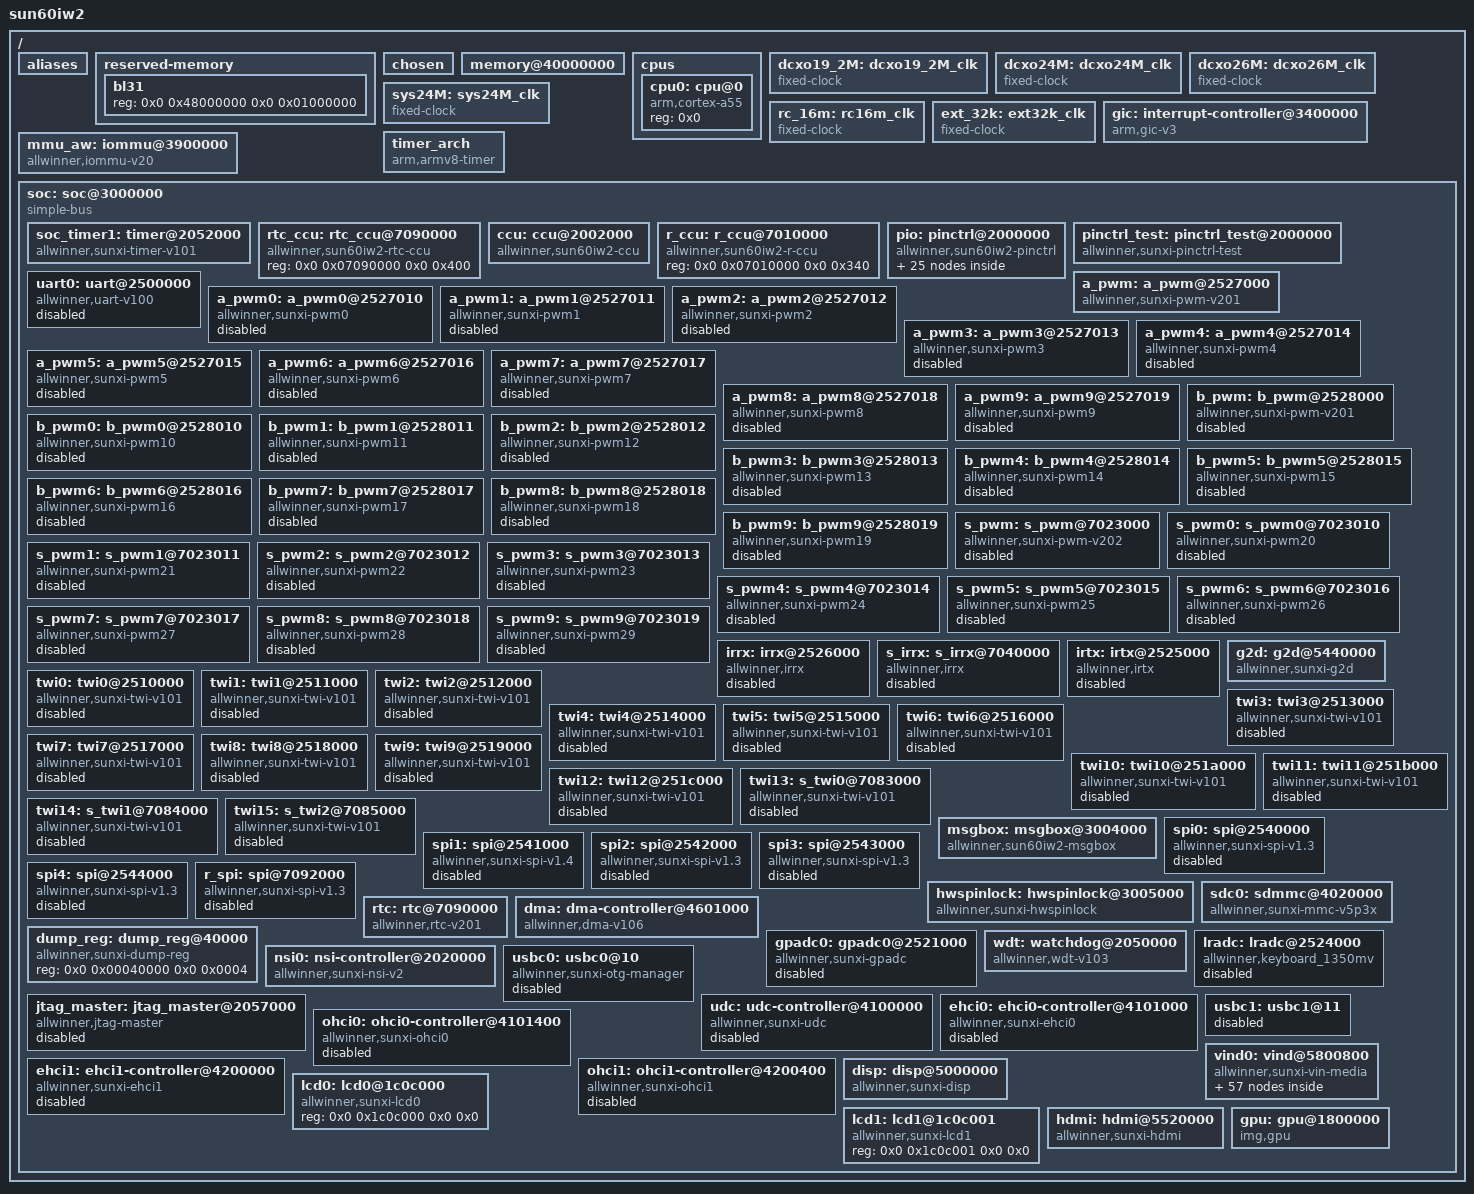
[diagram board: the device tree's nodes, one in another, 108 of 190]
// SPDX-License-Identifier: (GPL-2.0+ or MIT)
#include <dt-bindings/clock/sun60iw2-ccu.h>
#include <dt-bindings/clock/sun60iw2-rtc.h>
#include <dt-bindings/clock/sun60iw2-r-ccu.h>
#include <dt-bindings/gpio/gpio.h>
#include <dt-bindings/gpio/sun4i-gpio.h>
#include <dt-bindings/interrupt-controller/arm-gic.h>
#include <dt-bindings/reset/sun60iw2-ccu.h>
#include <dt-bindings/reset/sun60iw2-r-ccu.h>
#include <dt-bindings/power/a523-power.h>
#include <dt-bindings/phy/phy.h>
#include <dt-bindings/thermal/thermal.h>
#include <dt-bindings/spi/sunxi-spi.h>

/ {
	model = "sun60iw2";
	interrupt-parent = <&gic>;
	#address-cells = <2>;
	#size-cells = <2>;

	aliases {
		serial0 = &uart0;
		ir0 = &irrx;
		ir1 = &s_irrx;
		ir2 = &irtx;
		twi0 = &twi0;
		twi1 = &twi1;
		twi2 = &twi2;
		twi3 = &twi3;
		twi4 = &twi4;
		twi5 = &twi5;
		twi6 = &twi6;
		twi7 = &twi7;
		twi8 = &twi8;
		twi9 = &twi9;
		twi10 = &twi10;
		twi11 = &twi11;
		twi12 = &twi12;
		twi13 = &twi13;
		twi14 = &twi14;
		twi15 = &twi15;
		spi0 = &spi0;
		spi1 = &spi1;
		spi2 = &spi2;
		spi3 = &spi3;
		spi4 = &spi4;
		spi5 = &r_spi;
	};

	reserved-memory {
		#address-cells = <2>;
		#size-cells = <2>;
		ranges;

		bl31 {
			reg = <0x0 0x48000000 0x0 0x01000000>;
		};
	};

	chosen {
		bootargs = "earlyprintk=sunxi-uart,0x2500000 loglevel=8 initcall_debug=0 console=ttyS0 init=/init";
		linux,initrd-start = <0x0 0x0>;
		linux,initrd-end = <0x0 0x0>;
	};

	/* avoid panic when memory-node err(from uboot) */
	memory@40000000 {
		device_type = "memory";
		reg = <0x00000000 0x40000000 0x00000000 0x20000000>;
	};

	cpus {
		#address-cells = <1>;
		#size-cells = <0>;

		cpu0: cpu@0 {
			device_type = "cpu";
			compatible = "arm,cortex-a55";
			reg = <0x0>;
		};
	};

	dcxo19_2M: dcxo19_2M_clk {
		#clock-cells = <0>;
		compatible = "fixed-clock";
		clock-frequency = <19200000>;
		clock-output-names = "dcxo19_2M";
	};

	dcxo24M: dcxo24M_clk {
		#clock-cells = <0>;
		compatible = "fixed-clock";
		clock-frequency = <24000000>;
		clock-output-names = "dcxo24M";
	};

	dcxo26M: dcxo26M_clk {
		#clock-cells = <0>;
		compatible = "fixed-clock";
		clock-frequency = <26000000>;
		clock-output-names = "dcxo26M";
	};

	sys24M: sys24M_clk {
		#clock-cells = <0>;
		compatible = "fixed-clock";
		clock-frequency = <24000000>;
		clock-output-names = "sys24M";
	};

	rc_16m: rc16m_clk {
		#clock-cells = <0>;
		compatible = "fixed-clock";
		clock-frequency = <16000000>;
		clock-accuracy = <300000000>;
		clock-output-names = "rc-16m";
	};

	ext_32k: ext32k_clk {
		#clock-cells = <0>;
		compatible = "fixed-clock";
		clock-frequency = <32768>;
		clock-output-names = "ext-32k";
	};

	gic: interrupt-controller@3400000 {
		compatible = "arm,gic-v3";
		#interrupt-cells = <3>;
		#address-cells = <0>;
		interrupt-controller;
		reg = <0x0 0x03400000 0 0x10000>, /* GIC Dist */
		      <0x0 0x03460000 0 0xFF004>; /* GIC Re */
		interrupt-parent = <&gic>;
	};

	timer_arch {
		compatible = "arm,armv8-timer";
		interrupts = <GIC_PPI 13 (GIC_CPU_MASK_SIMPLE(4) | IRQ_TYPE_LEVEL_LOW)>,
			   <GIC_PPI 14 (GIC_CPU_MASK_SIMPLE(4) | IRQ_TYPE_LEVEL_LOW)>,
			   <GIC_PPI 11 (GIC_CPU_MASK_SIMPLE(4) | IRQ_TYPE_LEVEL_LOW)>,
			   <GIC_PPI 10 (GIC_CPU_MASK_SIMPLE(4) | IRQ_TYPE_LEVEL_LOW)>;
		clock-frequency = <24000000>;
		interrupt-parent = <&gic>;
		arm,no-tick-in-suspend;
	};

	mmu_aw: iommu@3900000 {
		compatible = "allwinner,iommu-v20";
		reg = <0x0 0x03900000 0x0 0x20000>;
		interrupts = <GIC_SPI 170 IRQ_TYPE_LEVEL_HIGH>,
		      <GIC_SPI 171 IRQ_TYPE_LEVEL_HIGH>;
		interrupt-names = "iommu-irq1","iommu-irq2";
		clocks = <&ccu CLK_IOMMU0_SYS_HCLK>,
		      <&ccu CLK_IOMMU0_SYS_PCLK>,
		      <&ccu CLK_IOMMU0_SYS_MCLK>,
		      <&ccu CLK_IOMMU1_SYS_HCLK>,
		      <&ccu CLK_IOMMU1_SYS_PCLK>,
		      <&ccu CLK_IOMMU1_SYS_MCLK>
		;
		clock-names = "iommu0-sys-hclk",
		      "iommu0-sys-pclk",
		      "iommu0-sys-mclk",
		      "iommu1-sys-hclk",
		      "iommu1-sys-pclk",
		      "iommu1-sys-mclk"
		;
		/* clock-frequency = <24000000>; */
		#iommu-cells = <2>;
		version=<0x16>;
		tlb_prefetch = <0x3007f>;
		tlb_invalid_mode = <0x1>;
		ptw_invalid_mode = <0x1>;
		masters = "USB", "CSI", "ISP", "VE_ENC", "dummy04", "dummy05",
			"VE_DEC0", "VE_DEC1", "DE0","DI","G2D","EINK", "DEBUG_MODE";
		valid_masters=<10>;
	};

	soc: soc@3000000 {
		compatible = "simple-bus";
		#address-cells = <2>;
		#size-cells = <2>;
		ranges;

		soc_timer1: timer@2052000 {
			compatible = "allwinner,sunxi-timer-v101";
			device_type = "soc_timer";
			reg = <0x0 0x02052000 0x0 0x400>;
			interrupt-parent = <&gic>;
			interrupts = <GIC_SPI 99 IRQ_TYPE_LEVEL_HIGH>;
			clocks = <&rtc_ccu CLK_OSC32K>;
		};

		rtc_ccu: rtc_ccu@7090000 {
			compatible = "allwinner,sun60iw2-rtc-ccu";
			reg = <0x0 0x07090000 0x0 0x400>;
			#clock-cells = <1>;
			#reset-cells = <1>;
		};

		ccu: ccu@2002000 {
			compatible = "allwinner,sun60iw2-ccu";
			reg = <0x0 0x02002000 0x0 0x2000>;
			clocks = <&dcxo24M>, <&rtc_ccu CLK_OSC32K>, <&rc_16m>;
			clock-names = "hosc", "losc", "iosc";
			#clock-cells = <1>;
			#reset-cells = <1>;
		};

		r_ccu: r_ccu@7010000 {
			compatible = "allwinner,sun60iw2-r-ccu";
			reg = <0x0 0x07010000 0x0 0x340>;
			#clock-cells = <1>;
			#reset-cells = <1>;
		};

		pio: pinctrl@2000000 {
			//#address-cells = <1>;
			//#size-cells = <0>;
			compatible = "allwinner,sun60iw2-pinctrl";
			reg = <0x0 0x02000000 0x0 0x800>;
			interrupts = <GIC_SPI 69 IRQ_TYPE_LEVEL_HIGH>,
				     <GIC_SPI 71 IRQ_TYPE_LEVEL_HIGH>,
				     <GIC_SPI 73 IRQ_TYPE_LEVEL_HIGH>,
				     <GIC_SPI 75 IRQ_TYPE_LEVEL_HIGH>,
				     <GIC_SPI 77 IRQ_TYPE_LEVEL_HIGH>,
				     <GIC_SPI 79 IRQ_TYPE_LEVEL_HIGH>,
				     <GIC_SPI 81 IRQ_TYPE_LEVEL_HIGH>;
			clocks = <&ccu CLK_APB1>, <&dcxo24M>, <&rtc_ccu CLK_OSC32K>;
			clock-names = "apb", "hosc", "losc";
			gpio-controller;
			#gpio-cells = <3>;
			interrupt-controller;
			#interrupt-cells = <3>;

			sdc0_pins_a: sdc0@0 {
				pins = "PF0", "PF1", "PF2",
						"PF3", "PF4", "PF5";
				function = "sd0";
				drive-strength = <40>;
				bias-pull-up;
				power-source = <3300>;
			};

			sdc0_pins_b: sdc0@1 {
				pins = "PF0", "PF1", "PF2",
						"PF3", "PF4", "PF5";
				function = "sd0";
				drive-strength = <40>;
				bias-pull-up;
				power-source = <1800>;
			};

			sdc0_pins_c: sdc0@2 {
				pins = "PF0", "PF1", "PF2",
						"PF3", "PF4", "PF5";
				function = "gpio_in";
			};

			/* TODO: add jtag pin */
			sdc0_pins_d: sdc0@3 {
				pins = "PF2", "PF4";
				function = "uart0";
				drive-strength = <10>;
				bias-pull-up;
			};

			sdc0_pins_e: sdc0@4 {
				pins = "PF0", "PF1", "PF3",
						"PF5";
				function = "jtag";
				drive-strength = <10>;
				bias-pull-up;
			};
			test_pins_a: test_pins@0 {
				pins = "PB0", "PB1";
				function = "test";
				drive-strength = <10>;
				bias-pull-up;
			};

			test_pins_b: test_pins@1 {
				pins = "PB0", "PB1";
				function = "gpio_in";
			};

			csi_mclk0_pins_a: csi_mclk0@0 {
				pins = "PE0";
				function = "mipi0";
				drive-strength = <20>;
			};

			csi_mclk0_pins_b: csi_mclk0@1 {
				pins = "PE0";
				function = "gpio_in";
			};

			csi_mclk1_pins_a: csi_mclk1@0 {
				pins = "PE5";
				function = "mipi1";
				drive-strength = <20>;
			};

			csi_mclk1_pins_b: csi_mclk1@1 {
				pins = "PE5";
				function = "gpio_in";
			};

			csi_mclk2_pins_a: csi_mclk2@0 {
				pins = "PE9";
				function = "mipi2";
				drive-strength = <20>;
			};

			csi_mclk2_pins_b: csi_mclk2@1 {
				pins = "PE9";
				function = "gpio_in";
			};

			ncsi0_bt656_pins_a: ncsi0_BT656@0 {
				pins = "PE0", "PE1", "PE2",
				"PE3", "PE4", "PE6", "PE7",
				"PE8", "PE9", "PE10";
				function = "ncsi";
				drive-strength = <20>;
			};

			ncsi0_bt656_pins_b: ncsi0_BT656@1 {
				pins = "PE0", "PE1", "PE2",
				"PE3", "PE4", "PE6", "PE7",
				"PE8", "PE9", "PE10";
				function = "gpio_in";
			};

			ncsi1_bt656_pins_a: ncsi1_BT656@0 {
				pins = "PK0", "PK1", "PK2",
				"PK19", "PK18", "PK17", "PK16",
				"PK15", "PK14", "PK13", "PK12";
				function = "ncsi";
				drive-strength = <20>;
			};

			ncsi1_bt656_pins_b: ncsi1_BT656@1 {
				pins = "PK0", "PK1", "PK2",
				"PK19", "PK18", "PK17", "PK16",
				"PK15", "PK14", "PK13", "PK12";
				function = "gpio_in";
			};

			ncsi1_bt1120_pins_a: ncsi1_BT1120@0 {
				pins = "PK0", "PK1", "PK2",
				"PK19", "PK18", "PK17", "PK16",
				"PK15", "PK14", "PK13", "PK12",
				"PK11", "PK10", "PK9", "PK8",
				"PK7", "PK6", "PK5", "PK4";
				function = "ncsi";
				drive-strength = <20>;
			};

			ncsi1_bt1120_pins_b: ncsi1_BT1120@1 {
				pins = "PK0", "PK1", "PK2",
				"PK19", "PK18", "PK17", "PK16",
				"PK15", "PK14", "PK13", "PK12",
				"PK11", "PK10", "PK9", "PK8",
				"PK7", "PK6", "PK5", "PK4";
				function = "gpio_in";
			};

			mipia_pins_a: mipia@0 {
				pins = "PK0", "PK1", "PK2", "PK3", "PK4",
				"PK5", "PK6", "PK7", "PK8", "PK9";
				function = "mcsia";
				drive-strength = <10>;

			};

			mipia_pins_b: mipia@1 {
				pins = "PK0", "PK1", "PK2", "PK3", "PK4",
				"PK5", "PK6", "PK7", "PK8", "PK9";
				function = "gpio_in";
			};

			mipib_pins_a: mipib@0 {
				pins = "PK10", "PK11", "PK12", "PK13", "PK14",
				"PK15", "PK16", "PK17", "PK18", "PK19";
				function = "mcsib";
				drive-strength = <10>;
			};

			mipib_pins_b: mipib@1 {
				pins = "PK10", "PK11", "PK12", "PK13", "PK14",
				"PK15", "PK16", "PK17", "PK18", "PK19";
				function = "gpio_in";

			};

			mipic_pins_a: mipic@0 {
				pins = "PK20", "PK21", "PK22",
					"PK23", "PK24", "PK25";
				function = "mcsic";
				drive-strength = <10>;

			};

			mipic_pins_b: mipic@1 {
				pins = "PK20", "PK21", "PK22",
					"PK23", "PK24", "PK25";
				function = "gpio_in";
			};
		};

		pinctrl_test: pinctrl_test@2000000 {
		      reg = <0x0 0x0 0x0 0x0>;
		      compatible = "allwinner,sunxi-pinctrl-test";
		      device_type = "pinctrl-test";
		      pinctrl-0 = <&test_pins_a>;
		      pinctrl-1 = <&test_pins_b>;
		      pinctrl-names = "default", "sleep";
		      test-gpios = <&pio PB 4 GPIO_ACTIVE_LOW>;
		      suspend-gpios = <&pio PC 5 GPIO_ACTIVE_LOW>;
		      wakeup-source;
		      interrupt-parent = <&pio>;
		      interrupts = <PB 6 IRQ_TYPE_LEVEL_HIGH>;
		};
		uart0: uart@2500000 {
			compatible = "allwinner,uart-v100";
			reg = <0x0 0x02500000 0x0 0x400>;
			interrupts = <GIC_SPI 2 IRQ_TYPE_LEVEL_HIGH>;
			clocks = <&ccu CLK_UART0>;
			resets = <&ccu RST_BUS_UART0>;
			uart0_port = <0>;
			uart0_type = <2>;
			status = "disabled";
		};

		a_pwm: a_pwm@2527000 {
			#pwm-cells = <0x3>;
			compatible = "allwinner,sunxi-pwm-v201";
			reg = <0x0 0x02527000 0x0 0x400>;
			clocks = <&ccu CLK_PWM0>;
			interrupts = <GIC_SPI 35 IRQ_TYPE_LEVEL_HIGH>;
			resets = <&ccu RST_BUS_PWM0>;
			pwm-number = <10>;
			pwm-base = <0x0>;
			sunxi-pwms = <&a_pwm0>, <&a_pwm1>, <&a_pwm2>, <&a_pwm3>, <&a_pwm4>,
			<&a_pwm5>, <&a_pwm6>, <&a_pwm7>, <&a_pwm8>, <&a_pwm9>;
			status = "okay";
		};

		a_pwm0: a_pwm0@2527010 {
			compatible = "allwinner,sunxi-pwm0";
			pinctrl-names = "active", "sleep";
			reg = <0x0 0x02527010 0x0 0x4>;
			reg_base = <0x02527000>;
			status = "disabled";
		};

		a_pwm1: a_pwm1@2527011 {
			compatible = "allwinner,sunxi-pwm1";
			pinctrl-names = "active", "sleep";
			reg = <0x0 0x02527011 0x0 0x4>;
			reg_base = <0x02527000>;
			status = "disabled";
		};

		a_pwm2: a_pwm2@2527012 {
			compatible = "allwinner,sunxi-pwm2";
			pinctrl-names = "active", "sleep";
			reg = <0x0 0x02527012 0x0 0x4>;
			reg_base = <0x02527000>;
			status = "disabled";
		};

		a_pwm3: a_pwm3@2527013 {
			compatible = "allwinner,sunxi-pwm3";
			pinctrl-names = "active", "sleep";
			reg = <0x0 0x02527013 0x0 0x4>;
			reg_base = <0x02527000>;
			status = "disabled";
		};

		a_pwm4: a_pwm4@2527014 {
			compatible = "allwinner,sunxi-pwm4";
			pinctrl-names = "active", "sleep";
			reg = <0x0 0x02527014 0x0 0x4>;
			reg_base = <0x02527000>;
			status = "disabled";
		};

		a_pwm5: a_pwm5@2527015 {
			compatible = "allwinner,sunxi-pwm5";
			pinctrl-names = "active", "sleep";
			reg = <0x0 0x02527015 0x0 0x4>;
			reg_base = <0x02527000>;
			status = "disabled";
		};

		a_pwm6: a_pwm6@2527016 {
			compatible = "allwinner,sunxi-pwm6";
			pinctrl-names = "active", "sleep";
			reg = <0x0 0x02527016 0x0 0x4>;
			reg_base = <0x02527000>;
			status = "disabled";
		};

		a_pwm7: a_pwm7@2527017 {
			compatible = "allwinner,sunxi-pwm7";
			pinctrl-names = "active", "sleep";
			reg = <0x0 0x02527017 0x0 0x4>;
			reg_base = <0x02527000>;
			status = "disabled";
		};

		a_pwm8: a_pwm8@2527018 {
			compatible = "allwinner,sunxi-pwm8";
			pinctrl-names = "active", "sleep";
			reg = <0x0 0x02527018 0x0 0x4>;
			reg_base = <0x02527000>;
			status = "disabled";
		};

		a_pwm9: a_pwm9@2527019 {
			compatible = "allwinner,sunxi-pwm9";
			pinctrl-names = "active", "sleep";
			reg = <0x0 0x02527019 0x0 0x4>;
			reg_base = <0x02527000>;
			status = "disabled";
		};

		b_pwm: b_pwm@2528000 {
			#pwm-cells = <0x3>;
			compatible = "allwinner,sunxi-pwm-v201";
			reg = <0x0 0x02528000 0x0 0x400>;
			clocks = <&ccu CLK_PWM1>;
			interrupts = <GIC_SPI 36 IRQ_TYPE_LEVEL_HIGH>;
			resets = <&ccu RST_BUS_PWM1>;
			pwm-number = <10>;
			pwm-base = <0xa>;
			sunxi-pwms = <&b_pwm0>, <&b_pwm1>, <&b_pwm2>, <&b_pwm3>,
			<&b_pwm4>, <&b_pwm5>, <&b_pwm6>, <&b_pwm7>, <&b_pwm8>, <&b_pwm9>;
			status = "disabled";
		};

		b_pwm0: b_pwm0@2528010 {
			compatible = "allwinner,sunxi-pwm10";
			pinctrl-names = "active", "sleep";
			reg = <0x0 0x02528010 0x0 0x4>;
			reg_base = <0x02528000>;
			status = "disabled";
		};

		b_pwm1: b_pwm1@2528011 {
			compatible = "allwinner,sunxi-pwm11";
			pinctrl-names = "active", "sleep";
			reg = <0x0 0x02528011 0x0 0x4>;
			reg_base = <0x02528000>;
			status = "disabled";
		};

		b_pwm2: b_pwm2@2528012 {
			compatible = "allwinner,sunxi-pwm12";
			pinctrl-names = "active", "sleep";
			reg = <0x0 0x02528012 0x0 0x4>;
			reg_base = <0x02528000>;
			status = "disabled";
		};

		b_pwm3: b_pwm3@2528013 {
			compatible = "allwinner,sunxi-pwm13";
			pinctrl-names = "active", "sleep";
			reg = <0x0 0x02528013 0x0 0x4>;
			reg_base = <0x02528000>;
			status = "disabled";
		};

		b_pwm4: b_pwm4@2528014 {
			compatible = "allwinner,sunxi-pwm14";
			pinctrl-names = "active", "sleep";
			reg = <0x0 0x02528014 0x0 0x4>;
			reg_base = <0x02528000>;
			status = "disabled";
		};

		b_pwm5: b_pwm5@2528015 {
			compatible = "allwinner,sunxi-pwm15";
			pinctrl-names = "active", "sleep";
			reg = <0x0 0x02528015 0x0 0x4>;
			reg_base = <0x02528000>;
			status = "disabled";
		};

		b_pwm6: b_pwm6@2528016 {
			compatible = "allwinner,sunxi-pwm16";
			pinctrl-names = "active", "sleep";
			reg = <0x0 0x02528016 0x0 0x4>;
			reg_base = <0x02528000>;
			status = "disabled";
		};

		b_pwm7: b_pwm7@2528017 {
			compatible = "allwinner,sunxi-pwm17";
			pinctrl-names = "active", "sleep";
			reg = <0x0 0x02528017 0x0 0x4>;
			reg_base = <0x02528000>;
			status = "disabled";
		};

		b_pwm8: b_pwm8@2528018 {
			compatible = "allwinner,sunxi-pwm18";
			pinctrl-names = "active", "sleep";
			reg = <0x0 0x02528018 0x0 0x4>;
			reg_base = <0x02528000>;
			status = "disabled";
		};

		b_pwm9: b_pwm9@2528019 {
			compatible = "allwinner,sunxi-pwm19";
			pinctrl-names = "active", "sleep";
			reg = <0x0 0x02528019 0x0 0x4>;
			reg_base = <0x02528000>;
			status = "disabled";
		};

		s_pwm: s_pwm@7023000 {
			#pwm-cells = <0x3>;
			compatible = "allwinner,sunxi-pwm-v202";
			reg = <0x0 0x07023000 0x0 0x400>;
			clocks = <&r_ccu CLK_R_PWM>,<&r_ccu CLK_R_BUS_PWM>;
			interrupts = <GIC_SPI 207 IRQ_TYPE_LEVEL_HIGH>;
			clock-names = "clk_pwm","clk_bus_pwm";
			resets = <&r_ccu RST_BUS_R_PWM>;
			pwm-number = <10>;
			pwm-base = <0x14>;
			sunxi-pwms = <&s_pwm0>, <&s_pwm1>, <&s_pwm2>, <&s_pwm3>,
			<&s_pwm4>, <&s_pwm5>, <&s_pwm6>, <&s_pwm7>, <&s_pwm8>, <&s_pwm9>;
			status = "disabled";
		};

		s_pwm0: s_pwm0@7023010 {
			compatible = "allwinner,sunxi-pwm20";
			pinctrl-names = "active", "sleep";
			reg = <0x0 0x07023010 0x0 0x4>;
			reg_base = <0x07023000>;
			status = "disabled";
		};

		s_pwm1: s_pwm1@7023011 {
			compatible = "allwinner,sunxi-pwm21";
			pinctrl-names = "active", "sleep";
			reg = <0x0 0x07023011 0x0 0x4>;
			reg_base = <0x07023000>;
			status = "disabled";
		};

		s_pwm2: s_pwm2@7023012 {
			compatible = "allwinner,sunxi-pwm22";
			pinctrl-names = "active", "sleep";
			reg = <0x0 0x07023012 0x0 0x4>;
			reg_base = <0x07023000>;
			status = "disabled";
		};

		s_pwm3: s_pwm3@7023013 {
			compatible = "allwinner,sunxi-pwm23";
			pinctrl-names = "active", "sleep";
			reg = <0x0 0x07023013 0x0 0x4>;
			reg_base = <0x07023000>;
			status = "disabled";
		};

		s_pwm4: s_pwm4@7023014 {
			compatible = "allwinner,sunxi-pwm24";
			pinctrl-names = "active", "sleep";
			reg = <0x0 0x07023014 0x0 0x4>;
			reg_base = <0x07023000>;
			status = "disabled";
		};

		s_pwm5: s_pwm5@7023015 {
			compatible = "allwinner,sunxi-pwm25";
			pinctrl-names = "active", "sleep";
			reg = <0x0 0x07023015 0x0 0x4>;
			reg_base = <0x07023000>;
			status = "disabled";
		};

		s_pwm6: s_pwm6@7023016 {
			compatible = "allwinner,sunxi-pwm26";
			pinctrl-names = "active", "sleep";
			reg = <0x0 0x07023016 0x0 0x4>;
			reg_base = <0x07023000>;
			status = "disabled";
		};

		s_pwm7: s_pwm7@7023017 {
			compatible = "allwinner,sunxi-pwm27";
			pinctrl-names = "active", "sleep";
			reg = <0x0 0x07023017 0x0 0x4>;
			reg_base = <0x07023000>;
			status = "disabled";
		};

		s_pwm8: s_pwm8@7023018 {
			compatible = "allwinner,sunxi-pwm28";
			pinctrl-names = "active", "sleep";
			reg = <0x0 0x07023018 0x0 0x4>;
			reg_base = <0x07023000>;
			status = "disabled";
		};

		s_pwm9: s_pwm9@7023019 {
			compatible = "allwinner,sunxi-pwm29";
			pinctrl-names = "active", "sleep";
			reg = <0x0 0x07023019 0x0 0x4>;
			reg_base = <0x07023000>;
			status = "disabled";
		};

		irrx: irrx@2526000 {
			compatible = "allwinner,irrx";
			reg = <0x0 0x02526000 0x0 0x400>;
			interrupts = <GIC_SPI 32 IRQ_TYPE_LEVEL_HIGH>;
			clocks = <&ccu CLK_BUS_IRRX>, <&dcxo24M>, <&ccu CLK_IRRX>;
			clock-names = "bus", "pclk", "mclk";
			resets = <&ccu RST_BUS_IRRX>;
			status = "disabled";
		};

		s_irrx: s_irrx@7040000 {
			compatible = "allwinner,irrx";
			reg = <0x0 0x07040000 0x0 0x400>;
			interrupts = <GIC_SPI 206 IRQ_TYPE_LEVEL_HIGH>;
			clocks = <&r_ccu CLK_R_BUS_IRRX>, <&dcxo24M>, <&r_ccu CLK_R_IRRX>;
			clock-names = "bus", "pclk", "mclk";
			resets = <&r_ccu RST_BUS_R_IRRX>;
			status = "disabled";
		};

		irtx: irtx@2525000 {
			compatible = "allwinner,irtx";
			reg = <0x0 0x02525000 0x0 0x400>;
			interrupts = <GIC_SPI 31 IRQ_TYPE_LEVEL_HIGH>;
			clocks = <&ccu CLK_BUS_IRTX>, <&dcxo24M>, <&ccu CLK_IRTX>;
			clock-names = "bus", "pclk", "mclk";
			resets = <&ccu RST_BUS_IRTX>;
			status = "disabled";
		};

		g2d: g2d@5440000 {
			compatible = "allwinner,sunxi-g2d";
			reg = <0x0 0x05440000 0x0 0x30000>;
			interrupts = <GIC_SPI 51 IRQ_TYPE_LEVEL_HIGH>;
			clocks = <&ccu CLK_BUS_G2D>, <&ccu CLK_G2D>;
			clock-names = "bus", "g2d";
			resets = <&ccu RST_BUS_G2D>;
			iommus = <&mmu_aw 10 1>;
			assigned-clocks = <&ccu CLK_G2D>;
			assigned-clock-rates = <300000000>;
		};

		twi0: twi0@2510000 {
			#address-cells = <1>;
			#size-cells = <0>;
			compatible = "allwinner,sunxi-twi-v101";
			device_type = "twi0";
			reg = <0x0 0x02510000 0x0 0x400>;
			interrupts = <GIC_SPI 11 IRQ_TYPE_LEVEL_HIGH>;
			clocks = <&ccu CLK_TWI0>;
			clock-names = "bus";
			resets = <&ccu RST_BUS_TWI0>;
			dmas = <&dma 37>, <&dma 37>;
			dma-names = "tx", "rx";
			status = "disabled";
		};

		twi1: twi1@2511000 {
			#address-cells = <1>;
			#size-cells = <0>;
			compatible = "allwinner,sunxi-twi-v101";
			device_type = "twi1";
			reg = <0x0 0x02511000 0x0 0x400>;
			interrupts = <GIC_SPI 12 IRQ_TYPE_LEVEL_HIGH>;
			clocks = <&ccu CLK_TWI1>;
			clock-names = "bus";
			resets = <&ccu RST_BUS_TWI1>;
			dmas = <&dma 38>, <&dma 38>;
			dma-names = "tx", "rx";
			status = "disabled";
		};

		twi2: twi2@2512000 {
			#address-cells = <1>;
			#size-cells = <0>;
			compatible = "allwinner,sunxi-twi-v101";
			device_type = "twi2";
			reg = <0x0 0x02512000 0x0 0x400>;
			interrupts = <GIC_SPI 13 IRQ_TYPE_LEVEL_HIGH>;
			clocks = <&ccu CLK_TWI2>;
			clock-names = "bus";
			resets = <&ccu RST_BUS_TWI2>;
			dmas = <&dma 39>, <&dma 39>;
			dma-names = "tx", "rx";
			status = "disabled";
		};

		twi3: twi3@2513000 {
			#address-cells = <1>;
			#size-cells = <0>;
			compatible = "allwinner,sunxi-twi-v101";
			device_type = "twi3";
			reg = <0x0 0x02513000 0x0 0x400>;
			interrupts = <GIC_SPI 14 IRQ_TYPE_LEVEL_HIGH>;
			clocks = <&ccu CLK_TWI3>;
			clock-names = "bus";
			resets = <&ccu RST_BUS_TWI3>;
			dmas = <&dma 40>, <&dma 40>;
			dma-names = "tx", "rx";
			status = "disabled";
		};

		twi4: twi4@2514000 {
			#address-cells = <1>;
			#size-cells = <0>;
			compatible = "allwinner,sunxi-twi-v101";
			device_type = "twi4";
			reg = <0x0 0x02514000 0x0 0x400>;
			interrupts = <GIC_SPI 15 IRQ_TYPE_LEVEL_HIGH>;
			clocks = <&ccu CLK_TWI4>;
			clock-names = "bus";
			resets = <&ccu RST_BUS_TWI4>;
			dmas = <&dma 41>, <&dma 41>;
			dma-names = "tx", "rx";
			status = "disabled";
		};

		twi5: twi5@2515000 {
			#address-cells = <1>;
			#size-cells = <0>;
			compatible = "allwinner,sunxi-twi-v101";
			device_type = "twi5";
			reg = <0x0 0x02515000 0x0 0x400>;
			interrupts = <GIC_SPI 16 IRQ_TYPE_LEVEL_HIGH>;
			clocks = <&ccu CLK_TWI5>;
			clock-names = "bus";
			resets = <&ccu RST_BUS_TWI5>;
			dmas = <&dma 42>, <&dma 42>;
			dma-names = "tx", "rx";
			status = "disabled";
		};

		twi6: twi6@2516000 {
			#address-cells = <1>;
			#size-cells = <0>;
			compatible = "allwinner,sunxi-twi-v101";
			device_type = "twi6";
			reg = <0x0 0x02516000 0x0 0x400>;
			interrupts = <GIC_SPI 17 IRQ_TYPE_LEVEL_HIGH>;
			clocks = <&ccu CLK_TWI6>;
			clock-names = "bus";
			resets = <&ccu RST_BUS_TWI6>;
			dmas = <&dma 43>, <&dma 43>;
			dma-names = "tx", "rx";
			status = "disabled";
		};

		twi7: twi7@2517000 {
			#address-cells = <1>;
			#size-cells = <0>;
			compatible = "allwinner,sunxi-twi-v101";
			device_type = "twi7";
			reg = <0x0 0x02517000 0x0 0x400>;
			interrupts = <GIC_SPI 18 IRQ_TYPE_LEVEL_HIGH>;
			clocks = <&ccu CLK_TWI7>;
			clock-names = "bus";
			resets = <&ccu RST_BUS_TWI7>;
			dmas = <&dma 44>, <&dma 44>;
			dma-names = "tx", "rx";
			status = "disabled";
		};

		twi8: twi8@2518000 {
			#address-cells = <1>;
			#size-cells = <0>;
			compatible = "allwinner,sunxi-twi-v101";
			device_type = "twi8";
			reg = <0x0 0x02518000 0x0 0x400>;
			interrupts = <GIC_SPI 19 IRQ_TYPE_LEVEL_HIGH>;
			clocks = <&ccu CLK_TWI8>;
			clock-names = "bus";
			resets = <&ccu RST_BUS_TWI8>;
			dmas = <&dma 45>, <&dma 45>;
			dma-names = "tx", "rx";
			status = "disabled";
		};

		twi9: twi9@2519000 {
			#address-cells = <1>;
			#size-cells = <0>;
			compatible = "allwinner,sunxi-twi-v101";
			device_type = "twi9";
			reg = <0x0 0x02519000 0x0 0x400>;
			interrupts = <GIC_SPI 20 IRQ_TYPE_LEVEL_HIGH>;
			clocks = <&ccu CLK_TWI9>;
			clock-names = "bus";
			resets = <&ccu RST_BUS_TWI9>;
			dmas = <&dma 58>, <&dma 58>;
			dma-names = "tx", "rx";
			status = "disabled";
		};

		twi10: twi10@251a000 {
			#address-cells = <1>;
			#size-cells = <0>;
			compatible = "allwinner,sunxi-twi-v101";
			device_type = "twi10";
			reg = <0x0 0x0251a000 0x0 0x400>;
			interrupts = <GIC_SPI 21 IRQ_TYPE_LEVEL_HIGH>;
			clocks = <&ccu CLK_TWI10>;
			clock-names = "bus";
			resets = <&ccu RST_BUS_TWI10>;
			dmas = <&dma 59>, <&dma 59>;
			dma-names = "tx", "rx";
			status = "disabled";
		};

		twi11: twi11@251b000 {
			#address-cells = <1>;
			#size-cells = <0>;
			compatible = "allwinner,sunxi-twi-v101";
			device_type = "twi11";
			reg = <0x0 0x0251b000 0x0 0x400>;
			interrupts = <GIC_SPI 22 IRQ_TYPE_LEVEL_HIGH>;
			clocks = <&ccu CLK_TWI11>;
			clock-names = "bus";
			resets = <&ccu RST_BUS_TWI11>;
			dmas = <&dma 60>, <&dma 60>;
			dma-names = "tx", "rx";
			status = "disabled";
		};

		twi12: twi12@251c000 {
			#address-cells = <1>;
			#size-cells = <0>;
			compatible = "allwinner,sunxi-twi-v101";
			device_type = "twi12";
			reg = <0x0 0x0251c000 0x0 0x400>;
			interrupts = <GIC_SPI 23 IRQ_TYPE_LEVEL_HIGH>;
			clocks = <&ccu CLK_TWI12>;
			clock-names = "bus";
			resets = <&ccu RST_BUS_TWI12>;
			dmas = <&dma 61>, <&dma 61>;
			dma-names = "tx", "rx";
			status = "disabled";
		};

		twi13: s_twi0@7083000 {
			#address-cells = <1>;
			#size-cells = <0>;
			compatible = "allwinner,sunxi-twi-v101";
			device_type = "twi13";
			reg = <0x0 0x07083000 0x0 0x400>;
			interrupts = <GIC_SPI 203 IRQ_TYPE_LEVEL_HIGH>;
			clocks = <&r_ccu CLK_R_TWI0>;
			clock-names = "bus";
			resets = <&r_ccu RST_BUS_R_TWI0>;
			dmas = <&dma 47>, <&dma 47>;
			dma-names = "tx", "rx";
			status = "disabled";
		};

		twi14: s_twi1@7084000 {
			#address-cells = <1>;
			#size-cells = <0>;
			compatible = "allwinner,sunxi-twi-v101";
			device_type = "twi14";
			reg = <0x0 0x07084000 0x0 0x400>;
			interrupts = <GIC_SPI 204 IRQ_TYPE_LEVEL_HIGH>;
			clocks = <&r_ccu CLK_R_TWI1>;
			clock-names = "bus";
			resets = <&r_ccu RST_BUS_R_TWI1>;
			dmas = <&dma 48>, <&dma 48>;
			dma-names = "tx", "rx";
			status = "disabled";
		};

		twi15: s_twi2@7085000 {
			#address-cells = <1>;
			#size-cells = <0>;
			compatible = "allwinner,sunxi-twi-v101";
			device_type = "twi15";
			reg = <0x0 0x07085000 0x0 0x400>;
			interrupts = <GIC_SPI 205 IRQ_TYPE_LEVEL_HIGH>;
			clocks = <&r_ccu CLK_R_TWI>;
			clock-names = "bus";
			resets = <&r_ccu RST_BUS_R_TWI>;
			dmas = <&dma 49>, <&dma 49>;
			dma-names = "tx", "rx";
			status = "disabled";
		};

		/*
		 * channel0~3  : arm -> cpus
		 */
		msgbox: msgbox@3004000 {
			compatible = "allwinner,sun60iw2-msgbox";
			#mbox-cells = <1>;
			reg = <0x0 0x03004000 0x0 0x1000>,
			      <0x0 0x07094000 0x0 0x1000>;
			interrupts = <GIC_SPI 0 IRQ_TYPE_LEVEL_HIGH>,
					<GIC_SPI 211 IRQ_TYPE_LEVEL_HIGH>;
			clocks = <&ccu CLK_MSGBOX0>;
			clock-names = "msgbox";
			resets = <&ccu RST_BUS_MSGBOX0>;
			reset-names = "rst";
			local_id = <0>;
			status = "okay";
		};

		spi0: spi@2540000 {
			#address-cells = <1>;
			#size-cells = <0>;
			compatible = "allwinner,sunxi-spi-v1.3";
			device_type = "spi0";
			reg = <0x0 0x02540000 0x0 0x1000>;
			interrupts = <GIC_SPI 24 IRQ_TYPE_LEVEL_HIGH>;
			clocks = <&ccu CLK_PLL_PERI0_300M>, <&ccu CLK_SPI0>, <&ccu CLK_BUS_SPI0>;
			clock-names = "pll", "mod", "bus";
			clock-frequency = <100000000>;
			resets = <&ccu RST_BUS_SPI0>;
			dmas = <&dma 23>, <&dma 23>;
			dma-names = "tx", "rx";
			status = "disabled";
		};

		spi1: spi@2541000 {
			#address-cells = <1>;
			#size-cells = <0>;
			compatible = "allwinner,sunxi-spi-v1.4";
			device_type = "spi1";
			reg = <0x0 0x02541000 0x0 0x1000>;
			interrupts = <GIC_SPI 25 IRQ_TYPE_LEVEL_HIGH>;
			clocks = <&ccu CLK_PLL_PERI0_300M>, <&ccu CLK_SPI1>, <&ccu CLK_BUS_SPI1>;
			clock-names = "pll", "mod", "bus";
			clock-frequency = <100000000>;
			resets = <&ccu RST_BUS_SPI1>;
			dmas = <&dma 24>, <&dma 24>;
			dma-names = "tx", "rx";
			status = "disabled";
		};

		spi2: spi@2542000 {
			#address-cells = <1>;
			#size-cells = <0>;
			compatible = "allwinner,sunxi-spi-v1.3";
			device_type = "spi2";
			reg = <0x0 0x02542000 0x0 0x1000>;
			interrupts = <GIC_SPI 26 IRQ_TYPE_LEVEL_HIGH>;
			clocks = <&ccu CLK_PLL_PERI0_300M>, <&ccu CLK_SPI2>, <&ccu CLK_BUS_SPI2>;
			clock-names = "pll", "mod", "bus";
			clock-frequency = <100000000>;
			resets = <&ccu RST_BUS_SPI2>;
			dmas = <&dma 25>, <&dma 25>;
			dma-names = "tx", "rx";
			status = "disabled";
		};

		spi3: spi@2543000 {
			#address-cells = <1>;
			#size-cells = <0>;
			compatible = "allwinner,sunxi-spi-v1.3";
			device_type = "spi3";
			reg = <0x0 0x02543000 0x0 0x1000>;
			interrupts = <GIC_SPI 27 IRQ_TYPE_LEVEL_HIGH>;
			clocks = <&ccu CLK_PLL_PERI0_300M>, <&ccu CLK_SPI3>, <&ccu CLK_BUS_SPI3>;
			clock-names = "pll", "mod", "bus";
			clock-frequency = <100000000>;
			resets = <&ccu RST_BUS_SPI3>;
			dmas = <&dma 26>, <&dma 26>;
			dma-names = "tx", "rx";
			status = "disabled";
		};

		spi4: spi@2544000 {
			#address-cells = <1>;
			#size-cells = <0>;
			compatible = "allwinner,sunxi-spi-v1.3";
			device_type = "spi4";
			reg = <0x0 0x02544000 0x0 0x1000>;
			interrupts = <GIC_SPI 28 IRQ_TYPE_LEVEL_HIGH>;
			clocks = <&ccu CLK_PLL_PERI0_300M>, <&ccu CLK_SPI4>, <&ccu CLK_BUS_SPI4>;
			clock-names = "pll", "mod", "bus";
			clock-frequency = <100000000>;
			resets = <&ccu RST_BUS_SPI4>;
			dmas = <&dma 54>, <&dma 54>;
			dma-names = "tx", "rx";
			status = "disabled";
		};

		r_spi: spi@7092000 {
			#address-cells = <1>;
			#size-cells = <0>;
			compatible = "allwinner,sunxi-spi-v1.3";
			device_type = "r_spi";
			reg = <0x0 0x07092000 0x0 0x1000>;
			interrupts = <GIC_SPI 210 IRQ_TYPE_LEVEL_HIGH>;
			clocks = <&ccu CLK_PLL_PERI0_300M>, <&r_ccu CLK_R_SPI>, <&r_ccu CLK_R_BUS_SPI>;
			clock-names = "pll", "mod", "bus";
			clock-frequency = <100000000>;
			resets = <&r_ccu RST_BUS_R_SPI>;
			dmas = <&dma 53>, <&dma 53>;
			dma-names = "tx", "rx";
			status = "disabled";
		};

		hwspinlock: hwspinlock@3005000 {
			compatible = "allwinner,sunxi-hwspinlock";
			reg = <0x0 0x3005000 0x0 0x1000>;
			#hwlock-cells = <1>;
			clocks = <&ccu CLK_SPINLOCK>;
			clock-names = "clk_hwspinlock_bus";
			resets = <&ccu RST_BUS_SPINLOCK>;
			reset-names = "rst";
			num-locks = <32>;
			status = "okay";
		};

		sdc0: sdmmc@4020000 {
			compatible = "allwinner,sunxi-mmc-v5p3x";
			device_type = "sdc0";
			reg = <0x0 0x04020000 0x0 0x1000>;
			interrupts = <GIC_SPI 161 IRQ_TYPE_LEVEL_HIGH>;
			clocks = <&sys24M>,
				 <&ccu CLK_SMHC0>,
				 <&ccu CLK_BUS_SMHC0>;
			clock-names = "osc24m","mmc","ahb";
			resets = <&ccu RST_BUS_SMHC0>;
			reset-names = "rst";
			pinctrl-names = "default","mmc_1v8","sleep","uart_jtag";
			pinctrl-0 = <&sdc0_pins_a>;
			pinctrl-1 = <&sdc0_pins_b>;
			pinctrl-2 = <&sdc0_pins_c>;
			pinctrl-3 = <&sdc0_pins_d &sdc0_pins_e>;
			max-frequency = <50000000>;
			bus-width = <4>;
			req-page-count = <2>;
			/*non-removable;*/
			/*broken-cd;*/
			/*cd-inverted*/
			/*cd-gpios = <&pio PF 6 GPIO_ACTIVE_LOW>;*/
			/* vmmc-supply = <&reg_3p3v>;*/
			/* vqmc-supply = <&reg_3p3v>;*/
			/* vdmc-supply = <&reg_3p3v>;*/
			/*vmmc = "vcc-card";*/
			/*vqmc = "";*/
			/*vdmc = "";*/
			cap-sd-highspeed;
			cap-wait-while-busy;
			/*sd-uhs-sdr50;*/
			/*sd-uhs-ddr50;*/
			/*cap-sdio-irq;*/
			/*keep-power-in-suspend;*/
			/*ignore-pm-notify;*/
			/*sunxi-power-save-mode;*/
			/*sunxi-dly-400k = <1 0 0 0>; */
			/*sunxi-dly-26M  = <1 0 0 0>;*/
			/*sunxi-dly-52M  = <1 0 0 0>;*/
			/*sunxi-dly-52M-ddr4  = <1 0 0 0>;*/
			/*sunxi-dly-52M-ddr8  = <1 0 0 0>;*/
			/*sunxi-dly-104M  = <1 0 0 0>;*/
			/*sunxi-dly-208M  = <1 0 0 0>;*/
			/*sunxi-dly-104M-ddr  = <1 0 0 0>;*/
			/*sunxi-dly-208M-ddr  = <1 0 0 0>;*/
			ctl-spec-caps = <0x408>;
			status = "okay";
		};

		rtc: rtc@7090000 {
			compatible = "allwinner,rtc-v201";
			device_type = "rtc";
			wakeup-source;
			reg = <0x0 0x07090000 0x0 0x320>;
			interrupts = <GIC_SPI 196 IRQ_TYPE_LEVEL_HIGH>;
			clocks = <&r_ccu CLK_RTC>, <&rtc_ccu CLK_RTC_1K>, <&rtc_ccu CLK_RTC_SPI>;
			clock-names = "r-ahb-rtc", "rtc-1k", "rtc-spi";
			resets = <&r_ccu RST_BUS_RTC>;
			gpr_cur_pos = <6>;
			gpr_bootcount_pos = <7>;
		};

		dma: dma-controller@4601000 {
			compatible = "allwinner,dma-v106";
			reg = <0x0 0x04601000 0x0 0x2000>;
			interrupts = <GIC_SPI 111 IRQ_TYPE_LEVEL_HIGH>;
			clocks = <&ccu CLK_DMA0_BUS>, <&ccu CLK_DMA0_MBUS>;
			clock-names = "bus", "mbus";
			dma-channels = <16>;
			dma-requests = <64>;
			resets = <&ccu RST_BUS_DMA0>;
			#dma-cells = <1>;
		};

		dump_reg:dump_reg@40000 {
			compatible = "allwinner,sunxi-dump-reg";
			reg = <0x0 0x00040000 0x0 0x0004>;
		};

		gpadc0: gpadc0@2521000 {
			compatible = "allwinner,sunxi-gpadc";
			reg = <0x0 0x02521000 0x0 0x400>;
			interrupts = <GIC_SPI 38 IRQ_TYPE_LEVEL_HIGH>;
			clocks = <&ccu CLK_GPADC0>;
			clock-names = "bus";
			resets = <&ccu RST_BUS_GPADC0>;
			status = "disabled";
		};

		wdt: watchdog@2050000 {
			compatible = "allwinner,wdt-v103";
			reg = <0x0 0x02050000 0x0 0x20>;
			interrupts = <GIC_SPI 106 IRQ_TYPE_LEVEL_HIGH>;
		};

		lradc: lradc@2524000 {
			compatible = "allwinner,keyboard_1350mv";
			reg = <0x0 0x02524000 0x0 0x100>;
			interrupts = <GIC_SPI 37 IRQ_TYPE_LEVEL_HIGH>;
			clocks = <&ccu CLK_LRADC>;
			resets = <&ccu RST_BUS_LRADC>;
			status = "disabled";
		};

		nsi0: nsi-controller@2020000 {
			compatible = "allwinner,sunxi-nsi-v2";
			interrupts = <GIC_SPI 43 IRQ_TYPE_LEVEL_HIGH>;
			reg = <0x0 0x02020000 0x0 0x10000>;
			clocks = <&ccu CLK_DDRPLL>, <&ccu CLK_MBUS>,<&ccu CLK_NSI>,<&ccu CLK_PLL_PERI0_800M>,<&ccu CLK_GIC>;
			clock-names = "pll", "bus", "nsi", "nsi-p","gic";
			resets = <&ccu RST_BUS_NSI>, <&ccu RST_BUS_NSI_CFG>;
			clock-frequency = <462000000>,<800000000>;
			#nsi-cells = <1>;
			clk_path_type=<1>;
			topology_type=<2>;
			master_clks = <6 2>,<10 4>,<18 2>,<19 2>,<20 2>;
		};

		jtag_master: jtag_master@2057000 {
			compatible = "allwinner,jtag-master";
			reg = <0x0 0x02057000 0x0 0x1000>;
			clocks = <&ccu CLK_APB2JTAG>;
			clock-names = "apb2jtag-clk";
			resets = <&ccu RST_BUS_APB2JTAG>;
			reset-names = "apb2jtag-rst";
			status = "disabled";
		};

		usbc0: usbc0@10 {
			device_type = "usbc0";
			compatible = "allwinner,sunxi-otg-manager";
			reg = <0x0 0x10 0x0 0x1000>;
			usb_port_type = <2>;
			usb_detect_type = <1>;
			usb_detect_mode = <0>;
			usb_id_gpio;
			usb_det_vbus_gpio;
			usb_regulator_io = "nocare";
			usb_wakeup_suspend = <0>;
			usb_luns = <3>;
			usb_serial_unique = <0>;
			usb_serial_number = "20080411";
			rndis_wceis = <1>;
			status = "disabled";
		};

		udc:udc-controller@4100000 {
			compatible = "allwinner,sunxi-udc";
			reg = <0x0 0x04100000 0x0 0x1000>, /* udc base */
			      <0x0 0x00000000 0x0 0x100>;  /* sram base */
			interrupts = <GIC_SPI 156 IRQ_TYPE_LEVEL_HIGH>;
			clocks = <&ccu CLK_USB0_DEVICE>;
			clock-names = "bus_otg";
			resets = <&ccu RST_USB_0_DEVICE>, <&ccu RST_USB_0_PHY_RSTN>;
			reset-names = "otg", "phy";
			status = "disabled";
		};

		ehci0:ehci0-controller@4101000 {
			compatible = "allwinner,sunxi-ehci0";
			reg = <0x0 0x04101000 0x0 0xFFF>,  /*hci0 base*/
			      <0x0 0x00000000 0x0 0x100>,  /*sram base*/
			      <0x0 0x04100000 0x0 0x1000>; /*otg base*/
			interrupts = <GIC_SPI 157 IRQ_TYPE_LEVEL_HIGH>;
			clocks = <&ccu CLK_USB0_EHCI>;
			clock-names = "bus_hci";
			resets = <&ccu RST_USB_0_EHCI>, <&ccu RST_USB_0_PHY_RSTN>;
			reset-names = "hci", "phy";
			hci_ctrl_no = <0>;
			status = "disabled";
		};

		ohci0:ohci0-controller@4101400 {
			compatible = "allwinner,sunxi-ohci0";
			reg = <0x0 0x04101400 0x0 0xFFF>,  /*hci0 base*/
			      <0x0 0x00000000 0x0 0x100>,  /*sram base*/
			      <0x0 0x04100000 0x0 0x1000>; /*otg base*/
			interrupts = <GIC_SPI 158 IRQ_TYPE_LEVEL_HIGH>;
			clocks = <&ccu CLK_USB0_OHCI>, <&ccu CLK_USB>;
			clock-names = "bus_hci", "ohci";
			resets = <&ccu RST_USB_0_OHCI>, <&ccu RST_USB_0_PHY_RSTN>;
			reset-names = "hci", "phy";
			hci_ctrl_no = <0>;
			status = "disabled";
		};

		usbc1: usbc1@11 {
			device_type = "usbc1";
			reg = <0x0 0x11 0x0 0x1000>;
			usb_regulator_io = "nocare";
			usb_wakeup_suspend = <0>;
			status = "disabled";
		};

		ehci1: ehci1-controller@4200000 {
			compatible = "allwinner,sunxi-ehci1";
			reg = <0x0 0x04200000 0x0 0xFFF>,  /*ehci1 base*/
			      <0x0 0x00000000 0x0 0x100>,  /*sram base*/
			      <0x0 0x04100000 0x0 0x1000>; /*otg base*/
			interrupts = <GIC_SPI 159 IRQ_TYPE_LEVEL_HIGH>;
			clocks = <&ccu CLK_USB1_EHCI>;
			clock-names = "bus_hci";
			resets = <&ccu RST_USB_1_EHCI>, <&ccu RST_USB_1_PHY_RSTN>;
			reset-names = "hci", "phy";
			hci_ctrl_no = <1>;
			status = "disabled";
		};

		ohci1: ohci1-controller@4200400 {
			compatible = "allwinner,sunxi-ohci1";
			reg = <0x0 0x04200400 0x0 0xFFF>,  /*ohci1 base*/
			      <0x0 0x00000000 0x0 0x100>,  /*sram base*/
			      <0x0 0x04100000 0x0 0x1000>; /*otg base*/
			interrupts = <GIC_SPI 160 IRQ_TYPE_LEVEL_HIGH>;
			clocks = <&ccu CLK_USB1_OHCI>, <&ccu CLK_USB1>;
			clock-names = "bus_hci", "ohci";
			resets = <&ccu RST_USB_1_OHCI>, <&ccu RST_USB_1_PHY_RSTN>;
			reset-names = "hci", "phy";
			hci_ctrl_no = <1>;
			status = "disabled";
		};

		vind0: vind@5800800 {
			compatible = "allwinner,sunxi-vin-media", "simple-bus";
			#address-cells = <2>;
			#size-cells = <2>;
			ranges;
			device_id = <0>;
			csi_top = <336000000>;
			csi_isp = <327000000>;
			reg = <0x0 0x05800800 0x0 0x200>,
				<0x0 0x05800000 0x0 0x800>,
				<0x0 0x05810000 0x0 0x100>;
			interrupts = <GIC_SPI 135 IRQ_TYPE_LEVEL_HIGH>;
			clocks = <&ccu CLK_CSI>, <&ccu CLK_VIDEO2PLL4X>,
				<&ccu CLK_CSI_MASTER0>, <&dcxo24M>, <&ccu CLK_VIDEO0PLL4X>,
				<&ccu CLK_CSI_MASTER1>, <&dcxo24M>, <&ccu CLK_VIDEO0PLL4X>,
				<&ccu CLK_CSI_MASTER2>, <&dcxo24M>, <&ccu CLK_VIDEO0PLL4X>,
				<&ccu CLK_ISP>, <&ccu CLK_VIDEO1PLL4X>,
				<&ccu CLK_BUS_CSI>, <&ccu CLK_CSI_MBUS>, <&ccu CLK_ISP_MBUS>;
			clock-names = "csi_top", "csi_top_src",
						"csi_mclk0", "csi_mclk0_24m", "csi_mclk0_pll",
						"csi_mclk1", "csi_mclk1_24m", "csi_mclk1_pll",
						"csi_mclk2", "csi_mclk2_24m", "csi_mclk2_pll",
						"csi_isp", "csi_isp_src",
						"csi_bus", "csi_mbus", "csi_isp_mbus";
			resets = <&ccu RST_BUS_CSI>, <>;
			reset-names = "csi_ret", "isp_ret";
			pinctrl-names = "mclk0-default", "mclk0-sleep", "mclk1-default", "mclk1-sleep",
							"mclk2-default", "mclk2-sleep";
			pinctrl-0 = <&csi_mclk0_pins_a>;
			pinctrl-1 = <&csi_mclk0_pins_b>;
			pinctrl-2 = <&csi_mclk1_pins_a>;
			pinctrl-3 = <&csi_mclk1_pins_b>;
			pinctrl-4 = <&csi_mclk2_pins_a>;
			pinctrl-5 = <&csi_mclk2_pins_b>;
			//power-domains = <&p >;
			status = "okay";

			csi0: csi@5820000 {
				compatible = "allwinner,sunxi-csi";
				reg = <0x0 0x05820000 0x0 0x1000>;
				interrupts = <GIC_SPI 125 IRQ_TYPE_LEVEL_HIGH>;
				device_id = <0>;
				status = "okay";
			};
			csi1: csi@5821000 {
				compatible = "allwinner,sunxi-csi";
				reg = <0x0 0x05821000 0x0 0x1000>;
				interrupts = <GIC_SPI 126 IRQ_TYPE_LEVEL_HIGH>;
				pinctrl-names = "default","sleep";
				pinctrl-0 = <&ncsi0_bt656_pins_a>;
				pinctrl-1 = <&ncsi0_bt656_pins_b>;
				device_id = <1>;
				status = "disabled";
			};
			csi2: csi@5822000 {
				compatible = "allwinner,sunxi-csi";
				reg = <0x0 0x05822000 0x0 0x1000>;
				interrupts = <GIC_SPI 127 IRQ_TYPE_LEVEL_HIGH>;
				pinctrl-names = "default","sleep";
				pinctrl-0 = <&ncsi1_bt656_pins_a>;
				pinctrl-1 = <&ncsi1_bt656_pins_b>;
				device_id = <2>;
				status = "disabled";
			};
			mipi0: mipi@5810100 {
				compatible = "allwinner,sunxi-mipi";
				reg = <0x0 0x05810100 0x0 0x100>,
					<0x0 0x05811000 0x0 0x400>;
				interrupts = <GIC_SPI 133 IRQ_TYPE_LEVEL_HIGH>;
				pinctrl-names = "mipi0-default","mipi0-sleep";
				pinctrl-0 = <&mipia_pins_a>;
				pinctrl-1 = <&mipia_pins_b>;
				device_id = <0>;
				status = "okay";
			};
			mipi1: mipi@5810200 {
				compatible = "allwinner,sunxi-mipi";
				reg = <0x0 0x05810200 0x0 0x100>,
					<0x0 0x05811400 0x0 0x400>;
				pinctrl-names = "mipi1-default","mipi1-sleep";
				pinctrl-0 = <&mipib_pins_a>;
				pinctrl-1 = <&mipib_pins_b>;
				device_id = <1>;
				status = "okay";
			};
			mipi2: mipi@5810300 {
				compatible = "allwinner,sunxi-mipi";
				reg = <0x0 0x05810300 0x0 0x100>,
					<0x0 0x05811800 0x0 0x400>;
				pinctrl-names = "mipi2-default","mipi2-sleep";
				pinctrl-0 = <&mipic_pins_a>;
				pinctrl-1 = <&mipic_pins_b>;
				device_id = <2>;
				status = "okay";
			};
			tdm0: tdm@5908000 {
				compatible = "allwinner,sunxi-tdm";
				reg = <0x0 0x05908000 0x0 0x400>;
				interrupts = <GIC_SPI 134 IRQ_TYPE_LEVEL_HIGH>;
				work_mode = <0x0>;
				device_id = <0>;
				iommus = <&mmu_aw 2 1>;
				status = "okay";
			};
			isp00:isp@5900000 {
				compatible = "allwinner,sunxi-isp";
				reg = <0x0 0x05900000 0x0 0x1300>;
				interrupts = <GIC_SPI 129 IRQ_TYPE_LEVEL_HIGH>;
				work_mode = <0x0>;
				device_id = <0>;
				iommus = <&mmu_aw 2 1>;
				status = "okay";
			};
			isp01:isp@58ffffc {
				compatible = "allwinner,sunxi-isp";
				reg = <0x0 0x058ffffc 0x0 0x1304>;
				interrupts = <GIC_SPI 130 IRQ_TYPE_LEVEL_HIGH>;
				work_mode = <0xff>;
				device_id = <1>;
				iommus = <&mmu_aw 2 1>;
				status = "disabled";
			};
			isp02:isp@58ffff8 {
				compatible = "allwinner,sunxi-isp";
				reg = <0x0 0x058ffff8 0x0 0x1308>;
				interrupts = <GIC_SPI 131 IRQ_TYPE_LEVEL_HIGH>;
				work_mode = <0xff>;
				device_id = <2>;
				iommus = <&mmu_aw 2 1>;
				status = "disabled";
			};
			isp03:isp@58ffff4 {
				compatible = "allwinner,sunxi-isp";
				reg = <0x0 0x058ffff4 0x0 0x130c>;
				interrupts = <GIC_SPI 132 IRQ_TYPE_LEVEL_HIGH>;
				work_mode = <0xff>;
				device_id = <3>;
				iommus = <&mmu_aw 2 1>;
				status = "disabled";
			};
			isp10:isp@4 {
				compatible = "allwinner,sunxi-isp";
				device_id = <4>;
				iommus = <&mmu_aw 2 1>;
				status = "disabled";
			};
			isp20:isp@5 {
				compatible = "allwinner,sunxi-isp";
				device_id = <5>;
				iommus = <&mmu_aw 2 1>;
				status = "disabled";
			};
			isp30:isp@6 {
				compatible = "allwinner,sunxi-isp";
				device_id = <6>;
				iommus = <&mmu_aw 2 1>;
				status = "disabled";
			};
			scaler00:scaler@5910000 {
				compatible = "allwinner,sunxi-scaler";
				reg = <0x0 0x05910000 0x0 0x400>;
				interrupts = <GIC_SPI 121 IRQ_TYPE_LEVEL_HIGH>;
				work_mode = <0x0>;
				device_id = <0>;
				iommus = <&mmu_aw 1 1>;
				status = "okay";
			};
			scaler01:scaler@590fffc {
				compatible = "allwinner,sunxi-scaler";
				reg = <0x0 0x0590fffc 0x0 0x404>;
				work_mode = <0xff>;
				device_id = <1>;
				iommus = <&mmu_aw 1 1>;
				status = "disabled";
			};
			scaler02:scaler@590fff8 {
				compatible = "allwinner,sunxi-scaler";
				reg = <0x0 0x0590fff8 0x0 0x408>;
				work_mode = <0xff>;
				device_id = <2>;
				iommus = <&mmu_aw 1 1>;
				status = "disabled";
			};
			scaler03:scaler@590fff4 {
				compatible = "allwinner,sunxi-scaler";
				reg = <0x0 0x0590fff4 0x0 0x40c>;
				work_mode = <0xff>;
				device_id = <3>;
				iommus = <&mmu_aw 1 1>;
				status = "disabled";
			};
			scaler10:scaler@5910400 {
				compatible = "allwinner,sunxi-scaler";
				reg = <0x0 0x05910400 0x0 0x400>;
				interrupts = <GIC_SPI 122 IRQ_TYPE_LEVEL_HIGH>;
				work_mode = <0x0>;
				device_id = <4>;
				iommus = <&mmu_aw 1 1>;
				status = "disabled";
			};
			scaler11:scaler@59103fc {
				compatible = "allwinner,sunxi-scaler";
				reg = <0x0 0x059103fc 0x0 0x404>;
				work_mode = <0xff>;
				device_id = <5>;
				iommus = <&mmu_aw 1 1>;
				status = "disabled";
			};
			scaler12:scaler@59103f8 {
				compatible = "allwinner,sunxi-scaler";
				reg = <0x0 0x059103f8 0x0 0x408>;
				work_mode = <0xff>;
				device_id = <6>;
				iommus = <&mmu_aw 1 1>;
				status = "disabled";
			};
			scaler13:scaler@59103f4 {
				compatible = "allwinner,sunxi-scaler";
				reg = <0x0 0x059103f4 0x0 0x40c>;
				work_mode = <0xff>;
				device_id = <7>;
				iommus = <&mmu_aw 1 1>;
				status = "disabled";
			};
			scaler20:scaler@5910800 {
				compatible = "allwinner,sunxi-scaler";
				reg = <0x0 0x05910800 0x0 0x400>;
				interrupts = <GIC_SPI 123 IRQ_TYPE_LEVEL_HIGH>;
				work_mode = <0x0>;
				device_id = <8>;
				iommus = <&mmu_aw 1 1>;
				status = "disabled";
			};
			scaler21:scaler@59107fc {
				compatible = "allwinner,sunxi-scaler";
				reg = <0x0 0x059107fc 0x0 0x404>;
				work_mode = <0xff>;
				device_id = <9>;
				iommus = <&mmu_aw 1 1>;
				status = "disabled";
			};
			scaler22:scaler@59107f8 {
				compatible = "allwinner,sunxi-scaler";
				reg = <0x0 0x059107f8 0x0 0x408>;
				work_mode = <0xff>;
				device_id = <10>;
				iommus = <&mmu_aw 1 1>;
				status = "disabled";
			};
			scaler23:scaler@59107f4 {
				compatible = "allwinner,sunxi-scaler";
				reg = <0x0 0x059107f4 0x0 0x40c>;
				work_mode = <0xff>;
				device_id = <11>;
				iommus = <&mmu_aw 1 1>;
				status = "disabled";
			};
			scaler30:scaler@5910c00 {
				compatible = "allwinner,sunxi-scaler";
				reg = <0x0 0x05910c00 0x0 0x400>;
				interrupts = <GIC_SPI 124 IRQ_TYPE_LEVEL_HIGH>;
				work_mode = <0x0>;
				device_id = <12>;
				iommus = <&mmu_aw 1 1>;
				status = "disabled";
			};
			scaler31:scaler@5910bfc {
				compatible = "allwinner,sunxi-scaler";
				reg = <0x0 0x05910bfc 0x0 0x404>;
				work_mode = <0xff>;
				device_id = <13>;
				iommus = <&mmu_aw 1 1>;
				status = "disabled";
			};
			scaler32:scaler@5910bf8 {
				compatible = "allwinner,sunxi-scaler";
				reg = <0x0 0x05910bf8 0x0 0x408>;
				work_mode = <0xff>;
				device_id = <14>;
				iommus = <&mmu_aw 1 1>;
				status = "disabled";
			};
			scaler33:scaler@5910bf4 {
				compatible = "allwinner,sunxi-scaler";
				reg = <0x0 0x05910bf4 0x0 0x40c>;
				work_mode = <0xff>;
				device_id = <15>;
				iommus = <&mmu_aw 1 1>;
				status = "disabled";
			};
			scaler40:scaler@16 {
				compatible = "allwinner,sunxi-scaler";
				device_id = <16>;
				iommus = <&mmu_aw 1 1>;
				status = "disabled";
			};
			scaler50:scaler@17 {
				compatible = "allwinner,sunxi-scaler";
				device_id = <17>;
				iommus = <&mmu_aw 1 1>;
				status = "disabled";
			};
			actuator0: actuator@2108180 {
				compatible = "allwinner,sunxi-actuator";
				device_type = "actuator0";
				reg = <0x0 0x02108180 0x0 0x10>;
				actuator0_name = "ad5820_act";
				actuator0_slave = <0x18>;
				actuator0_af_pwdn = <>;
				actuator0_afvdd = "afvcc-csi";
				actuator0_afvdd_vol = <2800000>;
				status = "disabled";
			};
			flash0: flash@2108190 {
				device_type = "flash0";
				compatible = "allwinner,sunxi-flash";
				reg = <0x0 0x02108190 0x0 0x10>;
				flash0_type = <2>;
				flash0_en = <>;
				flash0_mode = <>;
				flash0_flvdd = "";
				flash0_flvdd_vol = <>;
				device_id = <0>;
				status = "disabled";
			};
			sensor0: sensor@5812000 {
				reg = <0x0 0x05812000 0x0 0x10>;
				device_type = "sensor0";
				compatible = "allwinner,sunxi-sensor";
				sensor0_mname = "ov5640";
				sensor0_twi_cci_id = <2>;
				sensor0_twi_addr = <0x78>;
				sensor0_mclk_id = <0>;
				sensor0_pos = "rear";
				sensor0_isp_used = <0>;
				sensor0_fmt = <0>;
				sensor0_stby_mode = <0>;
				sensor0_vflip = <0>;
				sensor0_hflip = <0>;
				sensor0_iovdd-supply = <>;
				sensor0_iovdd_vol = <>;
				sensor0_avdd-supply = <>;
				sensor0_avdd_vol = <>;
				sensor0_dvdd-supply = <>;
				sensor0_dvdd_vol = <>;
				sensor0_power_en = <>;
				sensor0_reset = <>;
				sensor0_pwdn = <>;
				sensor0_sm_vs = <>;
				flash_handle = <&flash0>;
				act_handle = <&actuator0>;
				device_id = <0>;
				status	= "disabled";
			};
			sensor1: sensor@5812010 {
				reg = <0x0 0x05812010 0x0 0x10>;
				device_type = "sensor1";
				compatible = "allwinner,sunxi-sensor";
				sensor1_mname = "ov5647";
				sensor1_twi_cci_id = <3>;
				sensor1_twi_addr = <0x6c>;
				sensor1_mclk_id = <1>;
				sensor1_pos = "front";
				sensor1_isp_used = <0>;
				sensor1_fmt = <0>;
				sensor1_stby_mode = <0>;
				sensor1_vflip = <0>;
				sensor1_hflip = <0>;
				sensor1_iovdd-supply = <>;
				sensor1_iovdd_vol = <>;
				sensor1_avdd-supply = <>;
				sensor1_avdd_vol = <>;
				sensor1_dvdd-supply = <>;
				sensor1_dvdd_vol = <>;
				sensor1_power_en = <>;
				sensor1_reset = <>;
				sensor1_pwdn = <>;
				sensor1_sm_vs = <>;
				flash_handle = <>;
				act_handle = <>;
				device_id = <1>;
				status	= "disabled";
			};
			sensor2: sensor@5812020 {
				reg = <0x0 0x05812020 0x0 0x10>;
				device_type = "sensor2";
				compatible = "allwinner,sunxi-sensor";
				sensor2_mname = "imx386_mipi";
				sensor2_twi_cci_id = <3>;
				sensor2_twi_addr = <0x6c>;
				sensor2_mclk_id = <1>;
				sensor2_pos = "rear";
				sensor2_isp_used = <0>;
				sensor2_fmt = <0>;
				sensor2_stby_mode = <0>;
				sensor2_vflip = <0>;
				sensor2_hflip = <0>;
				sensor2_iovdd-supply = <>;
				sensor2_iovdd_vol = <>;
				sensor2_avdd-supply = <>;
				sensor2_avdd_vol = <>;
				sensor2_dvdd-supply = <>;
				sensor2_dvdd_vol = <>;
				sensor2_power_en = <>;
				sensor2_reset = <>;
				sensor2_pwdn = <>;
				sensor2_sm_vs = <>;
				flash_handle = <>;
				act_handle = <>;
				device_id = <2>;
				status	= "disabled";
			};
			sensor_list0:sensor_list@5812040 {
				reg = <0x0 0x05812040 0x0 0x10>;
				device_type = "sensor_list0";
				compatible = "allwinner,sunxi-sensor-list";
				csi_sel = <0>;
				sensor00_mname = "ov5675_mipi_b";
				sensor00_twi_addr = <0x60>;
				sensor00_type = <1>;
				sensor00_hflip =  <1>;
				sensor00_vflip = <0>;
				sensor00_act_used = <1>;
				sensor00_act_name = "dw9714_act";
				sensor00_act_twi_addr = <0x18>;
				sensor01_mname = "gc05a2_mipi_b";
				sensor01_twi_addr = <0x62>;
				sensor01_type = <1>;
				sensor01_hflip =  <0>;
				sensor01_vflip = <0>;
				sensor01_act_used = <1>;
				sensor01_act_name = "dw9714_act";
				sensor01_act_twi_addr = <0x18>;
				sensor02_mname = "gc5035_mipi_b";
				sensor02_twi_addr = <0x64>;
				sensor02_type = <1>;
				sensor02_hflip =  <0>;
				sensor02_vflip = <0>;
				sensor02_act_used = <1>;
				sensor02_act_name = "dw9714_act";
				sensor02_act_twi_addr = <0x18>;
				device_id = <0>;
				status	= "disabled";
			};
			sensor_list1:sensor_list@5812050 {
				reg = <0x0 0x05812050 0x0 0x10>;
				device_type = "sensor_list1";
				compatible = "allwinner,sunxi-sensor-list";
				csi_sel = <0>;
				sensor10_mname = "ov02a10_mipi_f";
				sensor10_twi_addr = <0x70>;
				sensor10_type = <1>;
				sensor10_hflip =  <1>;
				sensor10_vflip = <0>;
				sensor10_act_used = <0>;
				sensor10_act_name = "";
				sensor10_act_twi_addr = <>;
				sensor11_mname = "gc02m1_mipi_f";
				sensor11_twi_addr = <0x72>;
				sensor11_type = <1>;
				sensor11_hflip =  <1>;
				sensor11_vflip = <0>;
				sensor11_act_used = <0>;
				sensor11_act_name = "";
				sensor11_act_twi_addr = <>;
				sensor12_mname = "gc02m2_mipi_f";
				sensor12_twi_addr = <0x74>;
				sensor12_type = <1>;
				sensor12_hflip =  <0>;
				sensor12_vflip = <0>;
				sensor12_act_used = <0>;
				sensor12_act_name = "";
				sensor12_act_twi_addr = <>;
				device_id = <1>;
				status	= "disabled";
			};
			vinc00:vinc@5830000 {
				device_type = "vinc0";
				compatible = "allwinner,sunxi-vin-core";
				reg = <0x0 0x05830000 0x0 0x1000>;
				interrupts = <GIC_SPI 117 IRQ_TYPE_LEVEL_HIGH>;
				vinc0_csi_sel = <1>;
				vinc0_mipi_sel = <0xff>;
				vinc0_isp_sel = <0>;
				vinc0_isp_tx_ch = <0>;
				vinc0_tdm_rx_sel = <0>;
				vinc0_rear_sensor_sel = <0>;
				vinc0_front_sensor_sel = <0>;
				vinc0_sensor_list = <0>;
				device_id = <0>;
				work_mode = <0x0>;
				iommus = <&mmu_aw 1 1>;
				status = "okay";
			};
			vinc01:vinc@582fffc {
				device_type = "vinc1";
				compatible = "allwinner,sunxi-vin-core";
				reg = <0x0 0x0582fffc 0x0 0x1004>;
				vinc1_csi_sel = <1>;
				vinc1_mipi_sel = <0xff>;
				vinc1_isp_sel = <1>;
				vinc1_isp_tx_ch = <0>;
				vinc1_tdm_rx_sel = <1>;
				vinc1_rear_sensor_sel = <0>;
				vinc1_front_sensor_sel = <0>;
				vinc1_sensor_list = <0>;
				device_id = <1>;
				work_mode = <0xff>;
				iommus = <&mmu_aw 1 1>;
				status = "disabled";
			};
			vinc02:vinc@582fff8 {
				device_type = "vinc2";
				compatible = "allwinner,sunxi-vin-core";
				reg = <0x0 0x0582fff8 0x0 0x1008>;
				vinc2_csi_sel = <2>;
				vinc2_mipi_sel = <0xff>;
				vinc2_isp_sel = <2>;
				vinc2_isp_tx_ch = <2>;
				vinc2_tdm_rx_sel = <2>;
				vinc2_rear_sensor_sel = <0>;
				vinc2_front_sensor_sel = <0>;
				vinc2_sensor_list = <0>;
				device_id = <2>;
				work_mode = <0xff>;
				iommus = <&mmu_aw 1 1>;
				status = "disabled";
			};
			vinc03:vinc@582fff4 {
				device_type = "vinc3";
				compatible = "allwinner,sunxi-vin-core";
				reg = <0x0 0x0582fff4 0x0 0x100c>;
				vinc3_csi_sel = <0>;
				vinc3_mipi_sel = <0xff>;
				vinc3_isp_sel = <0>;
				vinc3_isp_tx_ch = <0>;
				vinc3_tdm_rx_sel = <0>;
				vinc3_rear_sensor_sel = <1>;
				vinc3_front_sensor_sel = <1>;
				vinc3_sensor_list = <0>;
				device_id = <3>;
				work_mode = <0xff>;
				iommus = <&mmu_aw 1 1>;
				status = "disabled";
			};
			vinc10:vinc@5831000 {
				device_type = "vinc4";
				compatible = "allwinner,sunxi-vin-core";
				reg = <0x0 0x05831000 0x0 0x1000>;
				interrupts = <GIC_SPI 118 IRQ_TYPE_LEVEL_HIGH>;
				vinc4_csi_sel = <1>;
				vinc4_mipi_sel = <0xff>;
				vinc4_isp_sel = <0>;
				vinc4_isp_tx_ch = <0>;
				vinc4_tdm_rx_sel = <0>;
				vinc4_rear_sensor_sel = <0>;
				vinc4_front_sensor_sel = <0>;
				vinc4_sensor_list = <0>;
				device_id = <4>;
				work_mode = <0x0>;
				iommus = <&mmu_aw 1 1>;
				status = "disabled";
			};
			vinc11:vinc@5830ffc {
				device_type = "vinc5";
				compatible = "allwinner,sunxi-vin-core";
				reg = <0x0 0x05830ffc 0x0 0x1004>;
				vinc5_csi_sel = <2>;
				vinc5_mipi_sel = <0xff>;
				vinc5_isp_sel = <1>;
				vinc5_isp_tx_ch = <1>;
				vinc5_tdm_rx_sel = <1>;
				vinc5_rear_sensor_sel = <0>;
				vinc5_front_sensor_sel = <0>;
				vinc5_sensor_list = <0>;
				device_id = <5>;
				work_mode = <0xff>;
				iommus = <&mmu_aw 1 1>;
				status = "disabled";
			};
			vinc12:vinc@5830ff8 {
				device_type = "vinc6";
				compatible = "allwinner,sunxi-vin-core";
				reg = <0x0 0x05830ff8 0x0 0x1008>;
				vinc6_csi_sel = <2>;
				vinc6_mipi_sel = <0xff>;
				vinc6_isp_sel = <0>;
				vinc6_isp_tx_ch = <0>;
				vinc6_tdm_rx_sel = <0>;
				vinc6_rear_sensor_sel = <0>;
				vinc6_front_sensor_sel = <0>;
				vinc6_sensor_list = <0>;
				device_id = <6>;
				work_mode = <0xff>;
				iommus = <&mmu_aw 1 1>;
				status = "disabled";
			};
			vinc13:vinc@5830ff4 {
				device_type = "vinc7";
				compatible = "allwinner,sunxi-vin-core";
				reg = <0x0 0x05830ff4 0x0 0x100c>;
				vinc7_csi_sel = <2>;
				vinc7_mipi_sel = <0xff>;
				vinc7_isp_sel = <0>;
				vinc7_isp_tx_ch = <0>;
				vinc7_tdm_rx_sel = <0>;
				vinc7_rear_sensor_sel = <0>;
				vinc7_front_sensor_sel = <0>;
				vinc7_sensor_list = <0>;
				device_id = <7>;
				work_mode = <0xff>;
				iommus = <&mmu_aw 1 1>;
				status = "disabled";
			};
			vinc20:vinc@5832000 {
				device_type = "vinc8";
				compatible = "allwinner,sunxi-vin-core";
				reg = <0x0 0x05832000 0x0 0x1000>;
				interrupts = <GIC_SPI 119 IRQ_TYPE_LEVEL_HIGH>;
				vinc8_csi_sel = <2>;
				vinc8_mipi_sel = <0xff>;
				vinc8_isp_sel = <4>;
				vinc8_isp_tx_ch = <3>;
				vinc8_tdm_rx_sel = <3>;
				vinc8_rear_sensor_sel = <0>;
				vinc8_front_sensor_sel = <0>;
				vinc8_sensor_list = <0>;
				device_id = <8>;
				work_mode = <0x0>;
				iommus = <&mmu_aw 1 1>;
				status = "disabled";
			};
			vinc21:vinc@5831ffc {
				device_type = "vinc9";
				compatible = "allwinner,sunxi-vin-core";
				reg = <0x0 0x05831ffc 0x0 0x1004>;
				vinc9_csi_sel = <2>;
				vinc9_mipi_sel = <0xff>;
				vinc9_isp_sel = <0>;
				vinc9_isp_tx_ch = <0>;
				vinc9_tdm_rx_sel = <0>;
				vinc9_rear_sensor_sel = <0>;
				vinc9_front_sensor_sel = <0>;
				vinc9_sensor_list = <0>;
				device_id = <9>;
				work_mode = <0xff>;
				iommus = <&mmu_aw 1 1>;
				status = "disabled";
			};
			vinc22:vinc@5831ff8 {
				device_type = "vinc10";
				compatible = "allwinner,sunxi-vin-core";
				reg = <0x0 0x05831ff8 0x0 0x1008>;
				vinc10_csi_sel = <2>;
				vinc10_mipi_sel = <0xff>;
				vinc10_isp_sel = <0>;
				vinc10_isp_tx_ch = <0>;
				vinc10_tdm_rx_sel = <0>;
				vinc10_rear_sensor_sel = <0>;
				vinc10_front_sensor_sel = <0>;
				vinc10_sensor_list = <0>;
				device_id = <10>;
				work_mode = <0xff>;
				iommus = <&mmu_aw 1 1>;
				status = "disabled";
			};
			vinc23:vinc@5831ff4 {
				device_type = "vinc11";
				compatible = "allwinner,sunxi-vin-core";
				reg = <0x0 0x05831ff4 0x0 0x100c>;
				vinc11_csi_sel = <2>;
				vinc11_mipi_sel = <0xff>;
				vinc11_isp_sel = <0>;
				vinc11_isp_tx_ch = <0>;
				vinc11_tdm_rx_sel = <0>;
				vinc11_rear_sensor_sel = <0>;
				vinc11_front_sensor_sel = <0>;
				vinc11_sensor_list = <0>;
				device_id = <11>;
				work_mode = <0xff>;
				iommus = <&mmu_aw 1 1>;
				status = "disabled";
			};
			vinc30:vinc@5833000 {
				device_type = "vinc12";
				compatible = "allwinner,sunxi-vin-core";
				reg = <0x0 0x05833000 0x0 0x1000>;
				interrupts = <GIC_SPI 120 IRQ_TYPE_LEVEL_HIGH>;
				vinc12_csi_sel = <2>;
				vinc12_mipi_sel = <0xff>;
				vinc12_isp_sel = <0>;
				vinc12_isp_tx_ch = <0>;
				vinc12_tdm_rx_sel = <0>;
				vinc12_rear_sensor_sel = <0>;
				vinc12_front_sensor_sel = <0>;
				vinc12_sensor_list = <0>;
				device_id = <12>;
				work_mode = <0x0>;
				iommus = <&mmu_aw 1 1>;
				status = "disabled";
			};
			vinc31:vinc@5832ffc {
				device_type = "vinc13";
				compatible = "allwinner,sunxi-vin-core";
				reg = <0x0 0x05832ffc 0x0 0x1004>;
				vinc13_csi_sel = <2>;
				vinc13_mipi_sel = <0xff>;
				vinc13_isp_sel = <0>;
				vinc13_isp_tx_ch = <0>;
				vinc13_tdm_rx_sel = <0>;
				vinc13_rear_sensor_sel = <0>;
				vinc13_front_sensor_sel = <0>;
				vinc13_sensor_list = <0>;
				device_id = <13>;
				work_mode = <0xff>;
				iommus = <&mmu_aw 1 1>;
				status = "disabled";
			};
			vinc32:vinc@5832ff8 {
				device_type = "vinc14";
				compatible = "allwinner,sunxi-vin-core";
				reg = <0x0 0x05832ff8 0x0 0x1008>;
				vinc14_csi_sel = <2>;
				vinc14_mipi_sel = <0xff>;
				vinc14_isp_sel = <0>;
				vinc14_isp_tx_ch = <0>;
				vinc14_tdm_rx_sel = <0>;
				vinc14_rear_sensor_sel = <0>;
				vinc14_front_sensor_sel = <0>;
				vinc14_sensor_list = <0>;
				device_id = <14>;
				work_mode = <0xff>;
				iommus = <&mmu_aw 1 1>;
				status = "disabled";
			};
			vinc33:vinc@5832ff4 {
				device_type = "vinc15";
				compatible = "allwinner,sunxi-vin-core";
				reg = <0x0 0x05832ff4 0x0 0x100c>;
				vinc15_csi_sel = <2>;
				vinc15_mipi_sel = <0xff>;
				vinc15_isp_sel = <0>;
				vinc15_isp_tx_ch = <0>;
				vinc15_tdm_rx_sel = <0>;
				vinc15_rear_sensor_sel = <0>;
				vinc15_front_sensor_sel = <0>;
				vinc15_sensor_list = <0>;
				device_id = <15>;
				work_mode = <0xff>;
				iommus = <&mmu_aw 1 1>;
				status = "disabled";
			};
			vinc40:vinc@5834000 {
				device_type = "vinc16";
				compatible = "allwinner,sunxi-vin-core";
				reg = <0x0 0x05834000 0x0 0x1000>;
				interrupts = <GIC_SPI 107 IRQ_TYPE_LEVEL_HIGH>;
				vinc16_csi_sel = <2>;
				vinc16_mipi_sel = <0xff>;
				vinc16_isp_sel = <0>;
				vinc16_isp_tx_ch = <0>;
				vinc16_tdm_rx_sel = <0>;
				vinc16_rear_sensor_sel = <0>;
				vinc16_front_sensor_sel = <0>;
				vinc16_sensor_list = <0>;
				device_id = <16>;
				work_mode = <0x0>;
				iommus = <&mmu_aw 1 1>;
				status = "disabled";
			};
			vinc50:vinc@5835000 {
				device_type = "vinc17";
				compatible = "allwinner,sunxi-vin-core";
				reg = <0x0 0x05835000 0x0 0x1000>;
				interrupts = <GIC_SPI 108 IRQ_TYPE_LEVEL_HIGH>;
				vinc17_csi_sel = <2>;
				vinc17_mipi_sel = <0xff>;
				vinc17_isp_sel = <0>;
				vinc17_isp_tx_ch = <0>;
				vinc17_tdm_rx_sel = <0>;
				vinc17_rear_sensor_sel = <0>;
				vinc17_front_sensor_sel = <0>;
				vinc17_sensor_list = <0>;
				device_id = <17>;
				work_mode = <0x0>;
				iommus = <&mmu_aw 1 1>;
				status = "disabled";
			};
		};

		disp: disp@5000000 {
			compatible = "allwinner,sunxi-disp";
			reg = <0x0 0x05000000 0x0 0x400000>, /* de0 */
			      <0x0 0x05500000 0x0 0x1000>, /* display_if_top0 */
			      <0x0 0x05510000 0x0 0x1000>, /* display_if_top1 */
			      <0x0 0x05501000 0x0 0x1000>, /* tcon_lcd0 */
			      <0x0 0x05502000 0x0 0x1000>, /* tcon_lcd1 */
			      <0x0 0x05503000 0x0 0x1000>, /* tcon_lcd2 */
			      <0x0 0x05730000 0x0 0x1000>, /* tcon_tv0 */
			      <0x0 0x05731000 0x0 0x1000>, /* tcon_tv1 */
			      <0x0 0x05506000 0x0 0x2000>, /* dsi0 */
			      <0x0 0x05508000 0x0 0x2000>; /* dsi1 */
			interrupts = <GIC_SPI 50 IRQ_TYPE_LEVEL_HIGH>, /* DE */
				     <GIC_SPI 34 IRQ_TYPE_LEVEL_HIGH>, /* DE freeze */
				     <GIC_SPI 54 IRQ_TYPE_LEVEL_HIGH>, /* tcon_lcd0 */
				     <GIC_SPI 55 IRQ_TYPE_LEVEL_HIGH>, /* tcon_lcd1 */
				     <GIC_SPI 56 IRQ_TYPE_LEVEL_HIGH>, /* tcon_lcd2 */
				     <GIC_SPI 57 IRQ_TYPE_LEVEL_HIGH>, /* tcon_tv0 */
				     <GIC_SPI 58 IRQ_TYPE_LEVEL_HIGH>, /* tcon_tv1 */
				     <GIC_SPI 59 IRQ_TYPE_LEVEL_HIGH>, /* dsi0 */
				     <GIC_SPI 60 IRQ_TYPE_LEVEL_HIGH>; /* dsi1 */
			clocks = <&ccu CLK_DE0>,
				 <&ccu CLK_BUS_DE0>,
				 <&ccu CLK_DE0>,
				 <&ccu CLK_BUS_DE0>,
				 <&ccu CLK_DPSS_TOP0>,
				 <&ccu CLK_DPSS_TOP0>,
				 <&ccu CLK_DPSS_TOP0>,
				 <&ccu CLK_DPSS_TOP1>,
				 <&ccu CLK_DPSS_TOP1>,
				 <&ccu CLK_VO0_TCONLCD0>,
				 <&ccu CLK_VO0_TCONLCD1>,
				 <&ccu CLK_VO0_TCONLCD2>,
				 <&ccu CLK_HDMI_TV>,
				 <&ccu CLK_EDP_TV>,
				 <&ccu CLK_BUS_VO0_TCONLCD0>,
				 <&ccu CLK_BUS_VO0_TCONLCD1>,
				 <&ccu CLK_BUS_VO0_TCONLCD2>,
				 <&ccu CLK_TCONTV0>,
				 <&ccu CLK_TCONTV1>,
				 <&ccu CLK_DSI0>,
				 <&ccu CLK_DSI1>,
				 <&ccu CLK_BUS_DSI0>,
				 <&ccu CLK_BUS_DSI1>,
				 <&ccu CLK_COMBPHY0>,
				 <&ccu CLK_COMBPHY1>;
			clock-names = 	"clk_de0",
					"clk_bus_de0",
					"clk_de1",
					"clk_bus_de1",
					"clk_bus_dpss_top0",
					"clk_bus_dpss_top1",
					"clk_bus_dpss_top2",
					"clk_bus_dpss_top3",
					"clk_bus_dpss_top4",
					"clk_tcon0",
					"clk_tcon1",
					"clk_tcon2",
					"clk_tcon3",
					"clk_tcon4",
					"clk_bus_tcon0",
					"clk_bus_tcon1",
					"clk_bus_tcon2",
					"clk_bus_tcon3",
					"clk_bus_tcon4",
					"clk_mipi_dsi0",
					"clk_mipi_dsi1",
					"clk_bus_mipi_dsi0",
					"clk_bus_mipi_dsi1",
					"clk_mipi_dsi_combphy0",
					"clk_mipi_dsi_combphy1";
			resets = <&ccu RST_BUS_DE0>,
				 <&ccu RST_BUS_DE_SY>,
				 <&ccu RST_BUS_DE0>,
				 <&ccu RST_BUS_DE_SY>,
				 <&ccu RST_BUS_DPSS_TOP0>,
				 <&ccu RST_BUS_DPSS_TOP0>,
				 <&ccu RST_BUS_DPSS_TOP0>,
				 <&ccu RST_BUS_DPSS_TOP1>,
				 <&ccu RST_BUS_DPSS_TOP1>,
				 <&ccu RST_BUS_VIDEO_OUT0>,
				 <&ccu RST_BUS_VIDEO_OUT0>,
				 <&ccu RST_BUS_VIDEO_OUT0>,
				 <&ccu RST_BUS_VIDEO_OUT1>,
				 <&ccu RST_BUS_VIDEO_OUT1>,
				 <&ccu RST_BUS_VO0_TCONLCD0>,
				 <&ccu RST_BUS_VO0_TCONLCD1>,
				 <&ccu RST_BUS_VO0_TCONLCD2>,
				 <&ccu RST_BUS_TCONTV0>,
				 <&ccu RST_BUS_TCONTV0>,
				 <&ccu RST_BUS_DSI0>,
				 <&ccu RST_BUS_DSI1>,
				 <&ccu RST_BUS_LVDS0>,
				 <&ccu RST_BUS_LVDS1>;
			reset-names = 	"rst_bus_de0",
					"rst_bus_de_sys0",
					"rst_bus_de1",
					"rst_bus_de_sys1",
					"rst_bus_dpss_top0",
					"rst_bus_dpss_top1",
					"rst_bus_dpss_top2",
					"rst_bus_dpss_top3",
					"rst_bus_dpss_top4",
					"rst_bus_video_out0",
					"rst_bus_video_out1",
					"rst_bus_video_out2",
					"rst_bus_video_out3",
					"rst_bus_video_out4",
					"rst_bus_tcon0",
					"rst_bus_tcon1",
					"rst_bus_tcon2",
					"rst_bus_tcon3",
					"rst_bus_tcon4",
					"rst_bus_mipi_dsi0",
					"rst_bus_mipi_dsi1",
					"rst_bus_lvds0",
					"rst_bus_lvds1";
			iommus = <&mmu_aw 8 0>;

			boot_disp = <0>;
			fb_base = <0>;
		};

		lcd0: lcd0@1c0c000 {
			compatible = "allwinner,sunxi-lcd0";
			reg = <0x0 0x1c0c000 0x0 0x0>;  /* Fake registers to avoid dtc compiling warnings */
			pinctrl-names = "active","sleep";
		};

		lcd1: lcd1@1c0c001 {
			compatible = "allwinner,sunxi-lcd1";
			reg = <0x0 0x1c0c001 0x0 0x0>;  /* Fake registers to avoid dtc compiling warnings */
			pinctrl-names = "active","sleep";
		};

		hdmi: hdmi@5520000 {
			compatible = "allwinner,sunxi-hdmi";
			reg = <0x0 0x05520000 0x0 0xFFFFF>;
			interrupts = <GIC_SPI 61 IRQ_TYPE_LEVEL_HIGH>;
			clocks = <&ccu CLK_HDMI_REF>,
				<&ccu CLK_HDMI_TV>,
				<&ccu CLK_HDMI>,
				<&ccu CLK_HDMI_SFR>,
				<&ccu CLK_HDCP_ESM>;
			clock-names = "clk_cec",	//cec
				      "clk_tcon_tv",	//tv
				      "clk_hdmi",	//busgating
				      "clk_hdmi_sfr",	//hdmiphypll
				      "clk_hdcp";	//hdcp
			resets = <&ccu RST_BUS_HDMI_HDCP>,
				<&ccu RST_BUS_HDMI_SUB>,
				<&ccu RST_BUS_HDMI_MAIN>;
			reset-names = "rst_bus_hdcp",
				      "rst_bus_sub",
				      "rst_bus_main";
			assigned-clocks = <&ccu CLK_HDMI>;
			assigned-clock-rates = <0>, <0>;

			status = "okay";
		};

		gpu: gpu@1800000 {
			device_type = "gpu";
			compatible = "img,gpu";
			reg = <0x0 0x01800000 0x0 0x8ffff>;
			interrupts = <GIC_SPI 63 IRQ_TYPE_LEVEL_HIGH>,
				     <GIC_SPI 64 IRQ_TYPE_LEVEL_HIGH>;
			interrupt-names = "IRQGPU", "IRQGPUDVFS";
			clocks = <&ccu CLK_GPU0PLL>, <&ccu CLK_GPU0>, <&ccu CLK_BUS_GPU0>;
			clock-names = "clk_parent", "clk", "clk_bus";
			resets = <&ccu RST_BUS_GPU0>;
			reset-names = "reset_bus";
		};

	};
};
